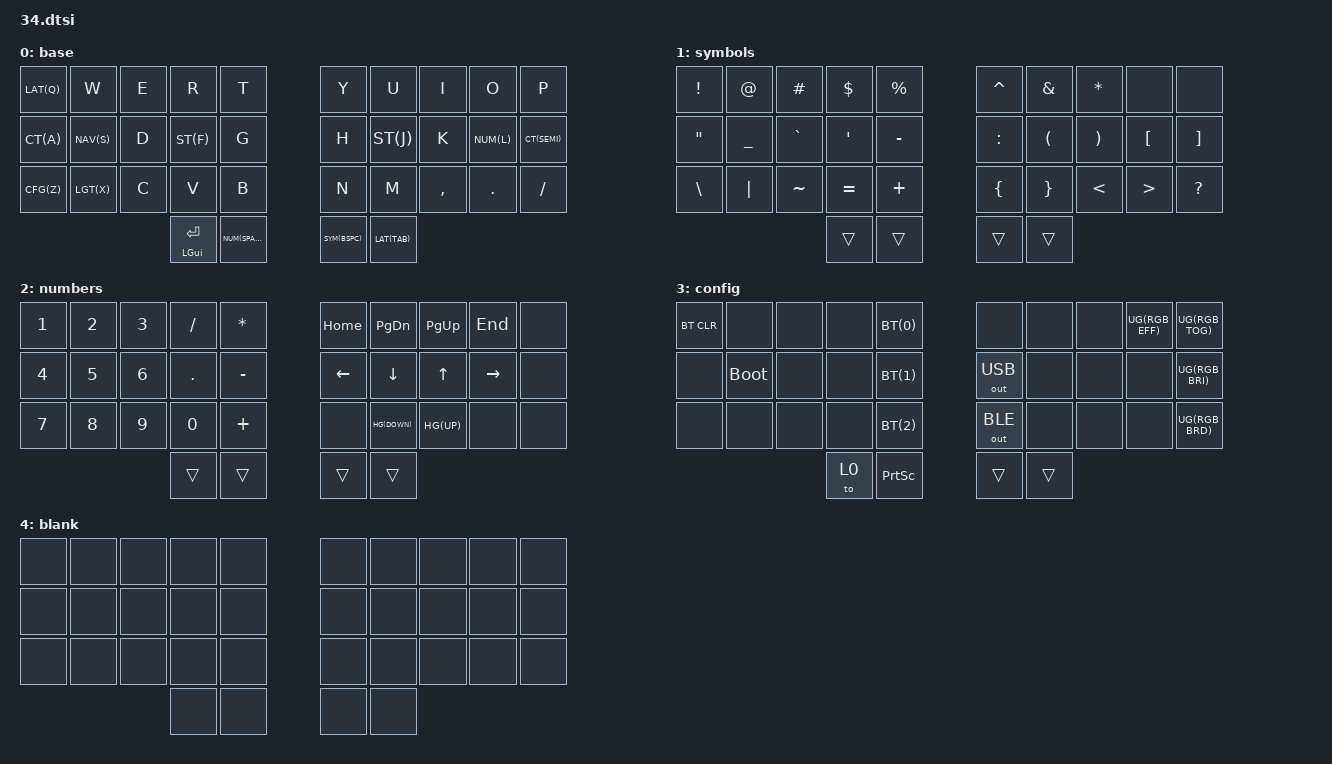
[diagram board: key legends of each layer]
#include <behaviors.dtsi>
#include <dt-bindings/zmk/backlight.h>
#include <dt-bindings/zmk/bt.h>
#include <dt-bindings/zmk/keys.h>
#include <dt-bindings/zmk/outputs.h>
#include <dt-bindings/zmk/rgb.h>

&caps_word {
    continue-list = <UNDERSCORE MINUS BSPC DEL N1 N2 N3 N4 N5 N6 N7 N8 N9 N0>;
};

// hold-preferred: trigger hold when other key is *pressed*
//       balanced: trigger hold when other key is *pressed and released*

&mt {
    flavor = "hold-preferred";
    tapping-term-ms = <200>;
    quick-tap-ms = <180>;
};

&lt {
    flavor = "balanced";
    tapping-term-ms = <200>;
    quick-tap-ms = <180>;
};


#define L1(k1) &lt 1 k1
#define SYM(k1) &lt 1 k1
#define L2(k1) &lt 2 k1
#define NAV(k1) &lt 2 k1
#define NUM(k1) &lt 2 k1
#define L3(k1) &lt 3 k1
#define CFG(k1) &lt 3 k1

// Alt when hold,k1 when tap
#define LAT(k1) &ht LALT k1
// GUI when hold, k1 when tap
#define LGT(k1) &ht LGUI k1
// shift when hold, k1 when tap
#define ST(k1) &ht LSHFT k1
// Ctrl when hold, k1 when tap
#define CT(k1) &ht LCTRL k1
// rgb
#define UG(k1) &rgb_ug k1

// hold preferred makes it easier to trigger hold
#define HOLD_PREFER_GUI(k1) &hp LGUI k1

// Hold GUI + x key press
#define HG(k1) &kp LG(k1)
#define ENTER &hp LGUI RET

#define BT(k1) &bt BT_SEL k1
#define BTC &bt BT_CLR

#define BOOT &bootloader

//     == layout and key index ==
//
// +---------------+---------------+
// | 0  1  2  3  4 |  5  6  7  8  9|
// |10 11 12 13 14 | 15 16 17 18 19|
// |20 21 22 23 24 | 25 26 27 28 29|
// +--------|30 31 | 32 33|--------+
//          +------+------+
/ {
    combos {
        compatible = "zmk,combos";
        lock {
            timeout-ms = <50>;
            key-positions = <0 9 20 29>;
            bindings = <&to 4>;
        };
        unlock {
            timeout-ms = <50>;
            key-positions = <1 8 21 28>;
            bindings = <&to 0>;
        };
        combo_esc {
            timeout-ms = <50>;
            key-positions = <0 1>;
            bindings = <&kp ESC>;
        };
        combo_sticky_gui {
            bindings = <&sk LGUI>;
            key-positions = <14 24>;
        };
        combo_bspc {
            bindings = <&kp BACKSPACE>;
            key-positions = <3 4>;
        };

        combo_vol_down {
            bindings = <&kp C_VOL_DN>;
            key-positions = <26 27>;
        };

        combo_vol_up {
            bindings = <&kp C_VOL_UP>;
            key-positions = <27 28>;
        };

        combo_caps_word {
            bindings = <&caps_word>;
            key-positions = <13 16>;
        };
        combo_sticky_ctrl_shift {
            bindings = <&sk LC(LSHFT)>;
            key-positions = <10 20>;
        };
        combo_layer_3 {
            bindings = <&to 3>;
            key-positions = <0 9>;
        };
    };

    behaviors {
        hp: hold_preferred {
            label = "HOLD PREFERRED";
            compatible = "zmk,behavior-hold-tap";
            #binding-cells = <2>;
            flavor = "hold-preferred";
            tapping-term-ms = <200>;
            quick-tap-ms = <180>;
            bindings = <&kp>, <&kp>;
        };
        ht: hold_tap {
            label = "TAP_HOLD";
            compatible = "zmk,behavior-hold-tap";
            #binding-cells = <2>;
            flavor = "balanced";
            tapping-term-ms = <200>;
            quick-tap-ms = <180>;
            bindings = <&kp>, <&kp>;
        };
        td0: td_0 {
            compatible = "zmk,behavior-tap-dance";
            label = "GUI_BACKTICK";
            #binding-cells = <0>;
            tapping-term-ms = <200>;
            bindings = <&kp LG(GRAVE)>;
        };
    };

//############################################################################################################
// * Having enter on left side to hit action when right hand operate mouse
//############################################################################################################

    keymap {
        compatible = "zmk,keymap";
        label = "3x5 keymap";

        base {
            bindings = <
//+---------+---------+---------+---------+---------+/*  */+---------+---------+---------+---------+---------+
   LAT(Q)    &kp W     &kp E     &kp R     &kp T     /*  */ &kp Y     &kp U     &kp I     &kp O     &kp P
//+---------+---------+---------+---------+---------+/*  */+---------+---------+---------+---------+---------+
   CT(A)     NAV(S)    &kp D     ST(F)     &kp G     /*  */ &kp H     ST(J)     &kp K     NUM(L)    CT(SEMI)
//+---------+---------+---------+---------+---------+/*  */+---------+---------+---------+---------+---------+
   CFG(Z)    LGT(X)    &kp C     &kp V     &kp B     /*  */ &kp N     &kp M     &kp COMMA &kp DOT   &kp FSLH
//+---------+---------+---------+---------+---------+/*  */+---------+---------+---------+---------+---------+
                                 ENTER     NUM(SPACE)/*  */ SYM(BSPC) LAT(TAB)
                              //================================================
            >;
        };

        symbols {
            bindings = <
//+---------+---------+---------+---------+---------+/*  */+---------+---------+---------+---------+---------+
   &kp EXCL  &kp AT    &kp HASH  &kp DLLR  &kp PRCNT /*  */ &kp CARET &kp AMPS  &kp STAR  &none     &none
//+---------+---------+---------+---------+---------+/*  */+---------+---------+---------+---------+---------+
   &kp DQT   &kp UNDER &kp GRAVE &kp SQT   &kp MINUS /*  */ &kp COLON &kp LPAR  &kp RPAR  &kp LBKT  &kp RBKT
//+---------+---------+---------+---------+---------+/*  */+---------+---------+---------+---------+---------+
   &kp BSLH  &kp PIPE  &kp TILDE &kp EQUAL &kp PLUS  /*  */ &kp LBRC  &kp RBRC  &kp LT    &kp GT    &kp QMARK
//+---------+---------+---------+---------+---------+/*  */+---------+---------+---------+---------+---------+
                                 &trans    &trans    /*  */ &trans    &trans
                              //================================================
            >;
        };

        numbers {
            bindings = <
//+---------+---------+---------+---------+---------+/*  */+---------+---------+---------+---------+---------+
   &kp N1    &kp N2    &kp N3    &kp SLASH &kp STAR  /*  */ &kp HOME  &kp PG_DN &kp PG_UP &kp END   &none
//+---------+---------+---------+---------+---------+/*  */+---------+---------+---------+---------+---------+
   &kp N4    &kp N5    &kp N6    &kp DOT   &kp MINUS /*  */ &kp LEFT  &kp DOWN  &kp UP    &kp RIGHT &none
//+---------+---------+---------+---------+---------+/*  */+---------+---------+---------+---------+---------+
   &kp N7    &kp N8    &kp N9    &kp N0    &kp PLUS  /*  */ &none     HG(DOWN)  HG(UP)    &none     &none
//+---------+---------+---------+---------+---------+/*  */+---------+---------+---------+---------+---------+
                                 &trans    &trans    /*  */ &trans    &trans
                              //================================================
            >;
        };

        config {
            bindings = <
//+---------+---------+---------+------+---------+/*  */+------------+---------+---------+-----------+-----------+
   BTC       &none     &none     &none  BT(0)     /*  */ &none        &none     &none     UG(RGB_EFF) UG(RGB_TOG)
//+---------+---------+---------+------+---------+/*  */+------------+---------+---------+-----------+-----------+
   &none     BOOT      &none     &none  BT(1)     /*  */ &out OUT_USB &none     &none     &none       UG(RGB_BRI)
//+---------+---------+---------+------+---------+/*  */+------------+---------+---------+-----------+-----------+
   &none     &none     &none     &none  BT(2)     /*  */ &out OUT_BLE &none     &none     &none       UG(RGB_BRD)
//+---------+---------+---------+------+---------+/*  */+------------+---------+---------+-----------+-----------+
                                 &to 0  &kp PSCRN /*  */ &trans       &trans
                              //================================================
            >;
        };

        blank {
            bindings = <
&none &none &none &none &none /* */ &none &none &none &none &none
&none &none &none &none &none /* */ &none &none &none &none &none
&none &none &none &none &none /* */ &none &none &none &none &none
                  &none &none /* */ &none &none
            >;
        };
    };
};
